# LargeDummyDevice register map
File version: 1.0
Registers are 32-bit, read-write, no defined reset value unless marked. A register's access mark holds for its fields unless they carry their own. Offsets are from the block's base; [hi:lo] are bit positions.

## PERIPHERAL_51
Base 0x40032000
0x04 REG_1 — Register 1
  [32:31] FIELD_19, [35:31] FIELD_30, [30] FIELD_2, [31:30] FIELD_11, [34:30] FIELD_25, [31:29] FIELD_3, [25:24] FIELD_29, [25:23] FIELD_10, [27:23] FIELD_24, [23:21] FIELD_15, [22:20] FIELD_5, [22:19] FIELD_26, [19:18] FIELD_6, [16:15] FIELD_4, [19:15] FIELD_22, [16:13] FIELD_7, [14:13] FIELD_16, [17:13] FIELD_17, [13] FIELD_21, [11] FIELD_1, [14:11] FIELD_27, [10] FIELD_18, [12:10] FIELD_20, [13:9] FIELD_12, [10:9] FIELD_13, [13:9] FIELD_23, [9] FIELD_31, [8:7] FIELD_14, [7:5] FIELD_9, [4:1] FIELD_28, [3:0] FIELD_8
0x08 REG_2 — Register 2
  [28:26] FIELD_13, [27:25] FIELD_6, [23] FIELD_9, [22] FIELD_3, [24:22] FIELD_4, [26:22] FIELD_5, [21:20] FIELD_16, [16] FIELD_2, [14] FIELD_10, [16:12] FIELD_1, [14:12] FIELD_15, [11:8] FIELD_8, [5] FIELD_12, [6:4] FIELD_11, [5:2] FIELD_7, [3:0] FIELD_14
0x0C REG_3 — Register 3
  [32:30] FIELD_7, [33:30] FIELD_12, [25:22] FIELD_8, [21] FIELD_6, [24:20] FIELD_11, [21:20] FIELD_17, [21:17] FIELD_1, [17] FIELD_4, [18:16] FIELD_13, [15] FIELD_2, [17:15] FIELD_10, [15:13] FIELD_18, [15:12] FIELD_9, [10:6] FIELD_3, [9:6] FIELD_15, [5] FIELD_16, [4:3] FIELD_5, [7:3] FIELD_19, [4:2] FIELD_14
0x10 REG_4 — Register 4
  [34:31] FIELD_3, [28:27] FIELD_2, [29:27] FIELD_8, [29:25] FIELD_4, [28:24] FIELD_1, [23:19] FIELD_7, [3] FIELD_6, [6:2] FIELD_5
0x14 REG_5 — Register 5
  [34:31] FIELD_2, [35:31] FIELD_6, [32:31] FIELD_13, [29:27] FIELD_3, [30:26] FIELD_8, [24:21] FIELD_5, [19] FIELD_10, [20:17] FIELD_11, [17:16] FIELD_7, [14:10] FIELD_9, [3:2] FIELD_12, [3:1] FIELD_4, [4:0] FIELD_1
0x18 REG_6 — Register 6
  [29:25] FIELD_9, [28:25] FIELD_12, [25:24] FIELD_6, [21] FIELD_10, [21:20] FIELD_3, [17] FIELD_7, [17] FIELD_13, [14] FIELD_1, [14] FIELD_11, [15:12] FIELD_4, [13:12] FIELD_5, [15:11] FIELD_8, [3:1] FIELD_2
0x1C REG_7 — Register 7
  [29] FIELD_23, [30:26] FIELD_6, [28:25] FIELD_7, [25:24] FIELD_18, [27:23] FIELD_10, [24:21] FIELD_5, [21] FIELD_11, [24:21] FIELD_22, [22:20] FIELD_9, [21:20] FIELD_20, [22:18] FIELD_19, [17:15] FIELD_15, [18:14] FIELD_24, [16:13] FIELD_14, [11] FIELD_13, [14:10] FIELD_3, [11:8] FIELD_21, [6] FIELD_2, [6] FIELD_8, [8:4] FIELD_1, [4] FIELD_17, [7:4] FIELD_25, [5:3] FIELD_4, [3] FIELD_16, [5:2] FIELD_12
0x20 REG_8 — Register 8
  [33:29] FIELD_9, [29] FIELD_12, [25:22] FIELD_15, [21] FIELD_3, [22:21] FIELD_4, [21] FIELD_5, [21] FIELD_10, [21] FIELD_14, [16] FIELD_19, [15:12] FIELD_6, [11:8] FIELD_22, [7:5] FIELD_11, [5:4] FIELD_8, [8:4] FIELD_17, [8:4] FIELD_20, [5:3] FIELD_13, [7:3] FIELD_18, [4:3] FIELD_23, [4:2] FIELD_2, [4:2] FIELD_16, [2:1] FIELD_21, [4:0] FIELD_1, [4:0] FIELD_7
0x24 REG_9 — Register 9
  [31] FIELD_3, [30] FIELD_15, [28:27] FIELD_7, [24] FIELD_5, [23] FIELD_1, [27:23] FIELD_2, [23:21] FIELD_17, [19:18] FIELD_11, [17:15] FIELD_6, [16:13] FIELD_13, [14:11] FIELD_8, [15:11] FIELD_16, [5] FIELD_4, [7:5] FIELD_10, [2] FIELD_9, [4:1] FIELD_12, [0] FIELD_14
0x28 REG_10 — Register 10
  [34:30] FIELD_1, [6:3] FIELD_2
0x2C REG_11 — Register 11
  [29] FIELD_7, [29] FIELD_15, [26:25] FIELD_9, [25] FIELD_10, [29:25] FIELD_12, [24] FIELD_14, [24:23] FIELD_5, [24:22] FIELD_3, [17:15] FIELD_16, [15:13] FIELD_2, [14:11] FIELD_11, [12:10] FIELD_4, [12:9] FIELD_1, [2] FIELD_8, [3:2] FIELD_13, [3:1] FIELD_6
0x30 REG_12 — Register 12
  [32:31] FIELD_1, [34:30] FIELD_2, [29] FIELD_3, [28:26] FIELD_9, [26:24] FIELD_8, [18:17] FIELD_6, [18:17] FIELD_13, [15] FIELD_11, [16:13] FIELD_7, [14:12] FIELD_12, [10:9] FIELD_5, [8] FIELD_4, [8:4] FIELD_10
0x34 REG_13 — Register 13
  [35:31] FIELD_11, [31:30] FIELD_26, [33:29] FIELD_9, [31:29] FIELD_20, [30:29] FIELD_27, [32:28] FIELD_12, [29:27] FIELD_1, [29:27] FIELD_10, [31:27] FIELD_13, [29:26] FIELD_25, [26:24] FIELD_3, [23:22] FIELD_22, [23:20] FIELD_15, [23:20] FIELD_19, [19] FIELD_8, [19] FIELD_18, [19:18] FIELD_7, [17:16] FIELD_14, [20:16] FIELD_17, [16:15] FIELD_5, [19:15] FIELD_24, [11:9] FIELD_2, [9:5] FIELD_6, [8:5] FIELD_16, [5] FIELD_23, [4] FIELD_21, [6:3] FIELD_4
0x38 REG_14 — Register 14
  [35:31] FIELD_15, [30] FIELD_20, [32:29] FIELD_21, [31:28] FIELD_1, [27] FIELD_4, [27:26] FIELD_13, [27:26] FIELD_28, [28:24] FIELD_8, [22:21] FIELD_25, [23:19] FIELD_14, [19] FIELD_27, [18] FIELD_12, [18:17] FIELD_16, [16:15] FIELD_22, [18:14] FIELD_9, [15:14] FIELD_10, [13] FIELD_6, [16:12] FIELD_3, [12] FIELD_5, [10] FIELD_23, [12:9] FIELD_7, [12:9] FIELD_24, [11:9] FIELD_29, [12:8] FIELD_30, [7] FIELD_11, [7] FIELD_17, [7] FIELD_31, [10:6] FIELD_26, [7:4] FIELD_19, [7:3] FIELD_2, [3] FIELD_18
0x3C REG_15 — Register 15
  [31:30] FIELD_5, [27] FIELD_8, [24:23] FIELD_1, [24:23] FIELD_6, [20:18] FIELD_2, [5:4] FIELD_3, [1] FIELD_4, [1:0] FIELD_7
0x40 REG_16 — Register 16
  [34:31] FIELD_4, [30:27] FIELD_2, [20:17] FIELD_5, [15] FIELD_1, [17:14] FIELD_6, [12:11] FIELD_3
0x44 REG_17 — Register 17
  [34:31] FIELD_4, [32:30] FIELD_11, [27:26] FIELD_1, [30:26] FIELD_3, [25:24] FIELD_12, [24:23] FIELD_5, [23:22] FIELD_9, [18:17] FIELD_10, [18:15] FIELD_7, [15:13] FIELD_8, [10:6] FIELD_2, [1:0] FIELD_6
0x48 REG_18 — Register 18
  [35:31] FIELD_3, [30:29] FIELD_32, [29:28] FIELD_15, [30:27] FIELD_6, [31:27] FIELD_16, [29:26] FIELD_27, [29:25] FIELD_7, [26:24] FIELD_10, [26:23] FIELD_24, [27:23] FIELD_29, [22:21] FIELD_20, [23:20] FIELD_2, [23:19] FIELD_9, [19] FIELD_22, [20:19] FIELD_25, [18] FIELD_5, [21:18] FIELD_13, [21:18] FIELD_31, [16:13] FIELD_1, [15:13] FIELD_28, [13:12] FIELD_12, [14:11] FIELD_17, [12:11] FIELD_21, [12:8] FIELD_11, [9:8] FIELD_14, [10:7] FIELD_8, [7:5] FIELD_23, [7:3] FIELD_18, [7:3] FIELD_26, [2] FIELD_30, [5:1] FIELD_4, [3:0] FIELD_19
0x4C REG_19 — Register 19
  [32:29] FIELD_3, [29] FIELD_18, [32:29] FIELD_19, [31:29] FIELD_23, [29:27] FIELD_5, [28:25] FIELD_9, [24:23] FIELD_2, [26:23] FIELD_4, [26:22] FIELD_16, [24:20] FIELD_29, [19] FIELD_6, [22:19] FIELD_11, [20:19] FIELD_13, [18] FIELD_12, [20:18] FIELD_21, [19:18] FIELD_24, [18:17] FIELD_15, [17:16] FIELD_20, [19:15] FIELD_30, [16:14] FIELD_17, [14:12] FIELD_7, [16:12] FIELD_27, [15:11] FIELD_25, [11:10] FIELD_14, [9] FIELD_28, [10:8] FIELD_10, [11:7] FIELD_26, [6:5] FIELD_1, [5:4] FIELD_8, [6:4] FIELD_22
0x50 REG_20 — Register 20
  [32:29] FIELD_12, [29:28] FIELD_10, [27] FIELD_6, [28:26] FIELD_5, [27:25] FIELD_14, [28:24] FIELD_1, [24:23] FIELD_16, [16:13] FIELD_15, [11:10] FIELD_2, [11:9] FIELD_4, [13:9] FIELD_11, [10:8] FIELD_17, [8:5] FIELD_7, [9:5] FIELD_13, [4:3] FIELD_9, [3:0] FIELD_3, [1:0] FIELD_8
0x54 REG_21 — Register 21
  [35:31] FIELD_23, [31:28] FIELD_7, [21] FIELD_4, [22:20] FIELD_25, [21:19] FIELD_2, [20:18] FIELD_15, [22:18] FIELD_19, [18:16] FIELD_1, [17:16] FIELD_17, [16:14] FIELD_6, [18:14] FIELD_22, [13] FIELD_12, [11:10] FIELD_9, [10] FIELD_10, [13:10] FIELD_13, [11:9] FIELD_11, [11:9] FIELD_20, [12:8] FIELD_24, [8] FIELD_26, [11:7] FIELD_3, [7] FIELD_8, [6] FIELD_5, [6:4] FIELD_14, [7:4] FIELD_27, [5:3] FIELD_16, [2] FIELD_18, [3:1] FIELD_21
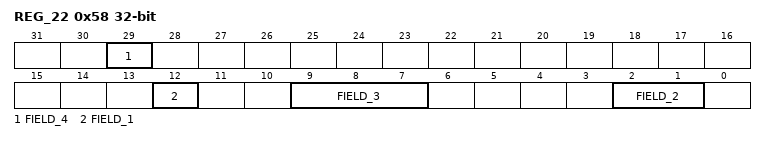
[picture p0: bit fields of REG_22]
0x58 REG_22 — Register 22
  [29] FIELD_4, [12] FIELD_1, [9:7] FIELD_3, [2:1] FIELD_2
0x5C REG_23 — Register 23
  [32:29] FIELD_3, [31:29] FIELD_30, [28:27] FIELD_14, [26] FIELD_6, [26] FIELD_8, [26] FIELD_13, [26:25] FIELD_21, [26:25] FIELD_29, [24:23] FIELD_22, [23:22] FIELD_2, [21:20] FIELD_15, [21:20] FIELD_17, [20:19] FIELD_16, [18:17] FIELD_4, [17] FIELD_7, [20:17] FIELD_23, [18:15] FIELD_18, [18:14] FIELD_27, [16:14] FIELD_28, [13] FIELD_24, [14:11] FIELD_20, [12:10] FIELD_11, [13:9] FIELD_26, [9:6] FIELD_25, [5] FIELD_1, [4] FIELD_5, [7:4] FIELD_19, [5:3] FIELD_12, [3:2] FIELD_9, [4:0] FIELD_10
0x60 REG_24 — Register 24
  [32:28] FIELD_2, [31:28] FIELD_4, [23] FIELD_3, [25:23] FIELD_14, [27:23] FIELD_21, [22] FIELD_1, [24:20] FIELD_13, [21:18] FIELD_8, [16] FIELD_16, [15:12] FIELD_6, [14:12] FIELD_15, [15:12] FIELD_20, [14:11] FIELD_5, [12:11] FIELD_10, [9:8] FIELD_9, [10:8] FIELD_17, [9:7] FIELD_12, [11:7] FIELD_18, [9:6] FIELD_22, [8:4] FIELD_11, [2] FIELD_7, [2] FIELD_19, [4:1] FIELD_23
